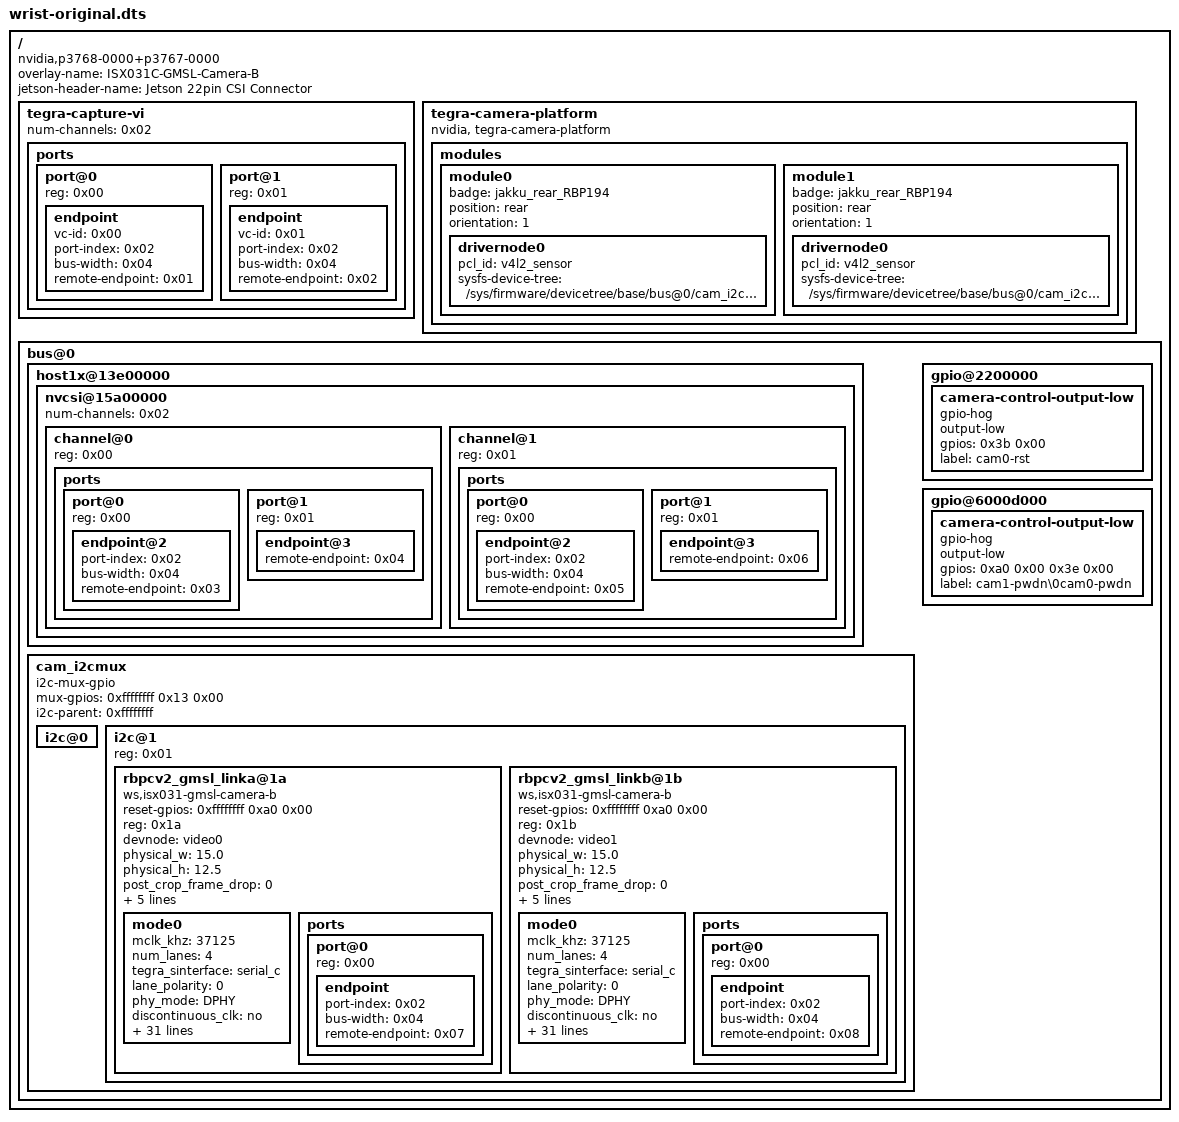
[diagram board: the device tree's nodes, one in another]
/dts-v1/;

/ {
	overlay-name = "ISX031C-GMSL-Camera-B";
	jetson-header-name = "Jetson 22pin CSI Connector";
	compatible = "nvidia,p3768-0000+p3767-0000\0nvidia,p3768-0000+p3767-0001\0nvidia,p3768-0000+p3767-0003\0nvidia,p3768-0000+p3767-0004\0nvidia,p3768-0000+p3767-0005\0nvidia,p3768-0000+p3767-0000-super\0nvidia,p3768-0000+p3767-0001-super\0nvidia,p3768-0000+p3767-0003-super\0nvidia,p3768-0000+p3767-0004-super\0nvidia,p3768-0000+p3767-0005-super";

	fragment@0 {
		target-path = "/";

		__overlay__ {

			tegra-capture-vi {
				num-channels = <0x02>;

				ports {
					#address-cells = <0x01>;
					#size-cells = <0x00>;

					port@0 {
						reg = <0x00>;
						phandle = <0x09>;

						endpoint {
							vc-id = <0x00>;
							port-index = <0x02>;
							bus-width = <0x04>;
							remote-endpoint = <0x01>;
							phandle = <0x04>;
						};
					};

					port@1 {
						reg = <0x01>;
						phandle = <0x0a>;

						endpoint {
							vc-id = <0x01>;
							port-index = <0x02>;
							bus-width = <0x04>;
							remote-endpoint = <0x02>;
							phandle = <0x06>;
						};
					};
				};
			};

			tegra-camera-platform {
				compatible = "nvidia, tegra-camera-platform";

				modules {

					module0 {
						badge = "jakku_rear_RBP194";
						position = "rear";
						orientation = "1";
						phandle = <0x0b>;

						drivernode0 {
							pcl_id = "v4l2_sensor";
							sysfs-device-tree = "/sys/firmware/devicetree/base/bus@0/cam_i2cmux/i2c@1/rbpcv2_gmsl_linka@1a";
							phandle = <0x0c>;
						};
					};

					module1 {
						badge = "jakku_rear_RBP194";
						position = "rear";
						orientation = "1";
						phandle = <0x0d>;

						drivernode0 {
							pcl_id = "v4l2_sensor";
							sysfs-device-tree = "/sys/firmware/devicetree/base/bus@0/cam_i2cmux/i2c@1/rbpcv2_gmsl_linkb@1b";
							phandle = <0x0e>;
						};
					};
				};
			};

			bus@0 {

				host1x@13e00000 {

					nvcsi@15a00000 {
						num-channels = <0x02>;
						#address-cells = <0x01>;
						#size-cells = <0x00>;

						channel@0 {
							reg = <0x00>;
							phandle = <0x0f>;

							ports {
								#address-cells = <0x01>;
								#size-cells = <0x00>;

								port@0 {
									reg = <0x00>;
									phandle = <0x10>;

									endpoint@2 {
										port-index = <0x02>;
										bus-width = <0x04>;
										remote-endpoint = <0x03>;
										phandle = <0x07>;
									};
								};

								port@1 {
									reg = <0x01>;
									phandle = <0x11>;

									endpoint@3 {
										remote-endpoint = <0x04>;
										phandle = <0x01>;
									};
								};
							};
						};

						channel@1 {
							reg = <0x01>;
							phandle = <0x12>;

							ports {
								#address-cells = <0x01>;
								#size-cells = <0x00>;

								port@0 {
									reg = <0x00>;
									phandle = <0x13>;

									endpoint@2 {
										port-index = <0x02>;
										bus-width = <0x04>;
										remote-endpoint = <0x05>;
										phandle = <0x08>;
									};
								};

								port@1 {
									reg = <0x01>;
									phandle = <0x14>;

									endpoint@3 {
										remote-endpoint = <0x06>;
										phandle = <0x02>;
									};
								};
							};
						};
					};
				};

				cam_i2cmux {
					status = "okay";
					compatible = "i2c-mux-gpio";
					#address-cells = <0x01>;
					#size-cells = <0x00>;
					mux-gpios = <0xffffffff 0x13 0x00>;
					i2c-parent = <0xffffffff>;

					i2c@0 {
					};

					i2c@1 {
						status = "okay";
						reg = <0x01>;
						#address-cells = <0x01>;
						#size-cells = <0x00>;

						rbpcv2_gmsl_linka@1a {
							reset-gpios = <0xffffffff 0xa0 0x00>;
							compatible = "ws,isx031-gmsl-camera-b";
							reg = <0x1a>;
							devnode = "video0";
							physical_w = "15.0";
							physical_h = "12.5";
							post_crop_frame_drop = "0";
							sensor_model = "isx031";
							use_sensor_mode_id = "true";
							channel = <0x01>;
							dser-addr = <0x48>;
							ser-addr = <0x40>;

							mode0 {
								mclk_khz = "37125";
								num_lanes = "4";
								tegra_sinterface = "serial_c";
								lane_polarity = "0";
								phy_mode = "DPHY";
								discontinuous_clk = "no";
								dpcm_enable = "false";
								cil_settletime = "0";
								active_w = "1920";
								active_h = "1536";
								mode_type = "yuv";
								pixel_phase = "uyvy";
								dynamic_pixel_bit_depth = "16";
								csi_pixel_bit_depth = "16";
								readout_orientation = "0";
								line_length = "2200";
								inherent_gain = "1";
								pix_clk_hz = "74250000";
								serdes_pix_clk_hz = "375000000";
								gain_factor = "10";
								framerate_factor = "1000000";
								exposure_factor = "1000000";
								min_gain_val = "16";
								max_gain_val = "170";
								step_gain_val = "1";
								default_gain = "16";
								min_hdr_ratio = "1";
								max_hdr_ratio = "1";
								min_framerate = "30000000";
								max_framerate = "30000000";
								step_framerate = "1";
								default_framerate = "30000000";
								min_exp_time = "30";
								max_exp_time = "660000";
								step_exp_time = "1";
								default_exp_time = "33334";
								embedded_metadata_height = "0";
							};

							ports {
								#address-cells = <0x01>;
								#size-cells = <0x00>;

								port@0 {
									reg = <0x00>;

									endpoint {
										status = "okay";
										port-index = <0x02>;
										bus-width = <0x04>;
										remote-endpoint = <0x07>;
										phandle = <0x03>;
									};
								};
							};
						};

						rbpcv2_gmsl_linkb@1b {
							reset-gpios = <0xffffffff 0xa0 0x00>;
							compatible = "ws,isx031-gmsl-camera-b";
							reg = <0x1b>;
							devnode = "video1";
							physical_w = "15.0";
							physical_h = "12.5";
							post_crop_frame_drop = "0";
							sensor_model = "isx031";
							use_sensor_mode_id = "true";
							channel = <0x01>;
							dser-addr = <0x48>;
							ser-addr = <0x40>;

							mode0 {
								mclk_khz = "37125";
								num_lanes = "4";
								tegra_sinterface = "serial_c";
								lane_polarity = "0";
								phy_mode = "DPHY";
								discontinuous_clk = "no";
								dpcm_enable = "false";
								cil_settletime = "0";
								active_w = "1920";
								active_h = "1536";
								mode_type = "yuv";
								pixel_phase = "uyvy";
								dynamic_pixel_bit_depth = "16";
								csi_pixel_bit_depth = "16";
								readout_orientation = "0";
								line_length = "2200";
								inherent_gain = "1";
								pix_clk_hz = "74250000";
								serdes_pix_clk_hz = "375000000";
								gain_factor = "10";
								framerate_factor = "1000000";
								exposure_factor = "1000000";
								min_gain_val = "16";
								max_gain_val = "170";
								step_gain_val = "1";
								default_gain = "16";
								min_hdr_ratio = "1";
								max_hdr_ratio = "1";
								min_framerate = "30000000";
								max_framerate = "30000000";
								step_framerate = "1";
								default_framerate = "30000000";
								min_exp_time = "30";
								max_exp_time = "660000";
								step_exp_time = "1";
								default_exp_time = "33334";
								embedded_metadata_height = "0";
							};

							ports {
								#address-cells = <0x01>;
								#size-cells = <0x00>;

								port@0 {
									reg = <0x00>;

									endpoint {
										status = "okay";
										port-index = <0x02>;
										bus-width = <0x04>;
										remote-endpoint = <0x08>;
										phandle = <0x05>;
									};
								};
							};
						};
					};
				};

				gpio@2200000 {

					camera-control-output-low {
						gpio-hog;
						output-low;
						gpios = <0x3b 0x00>;
						label = "cam0-rst";
					};
				};

				gpio@6000d000 {

					camera-control-output-low {
						gpio-hog;
						output-low;
						gpios = <0xa0 0x00 0x3e 0x00>;
						label = "cam1-pwdn\0cam0-pwdn";
					};
				};
			};
		};
	};

	__symbols__ {
		vi_port0 = "/fragment@0/__overlay__/tegra-capture-vi/ports/port@0";
		rbpcv2_gmsl_vi_in0 = "/fragment@0/__overlay__/tegra-capture-vi/ports/port@0/endpoint";
		vi_port1 = "/fragment@0/__overlay__/tegra-capture-vi/ports/port@1";
		rbpcv2_gmsl_vi_in1 = "/fragment@0/__overlay__/tegra-capture-vi/ports/port@1/endpoint";
		cam_module0 = "/fragment@0/__overlay__/tegra-camera-platform/modules/module0";
		cam_module0_drivernode0 = "/fragment@0/__overlay__/tegra-camera-platform/modules/module0/drivernode0";
		cam_module1 = "/fragment@0/__overlay__/tegra-camera-platform/modules/module1";
		cam_module1_drivernode0 = "/fragment@0/__overlay__/tegra-camera-platform/modules/module1/drivernode0";
		csi_chan0 = "/fragment@0/__overlay__/bus@0/host1x@13e00000/nvcsi@15a00000/channel@0";
		csi_chan0_port0 = "/fragment@0/__overlay__/bus@0/host1x@13e00000/nvcsi@15a00000/channel@0/ports/port@0";
		rbpcv2_gmsl_csi_in0 = "/fragment@0/__overlay__/bus@0/host1x@13e00000/nvcsi@15a00000/channel@0/ports/port@0/endpoint@2";
		csi_chan0_port1 = "/fragment@0/__overlay__/bus@0/host1x@13e00000/nvcsi@15a00000/channel@0/ports/port@1";
		rbpcv2_gmsl_csi_out0 = "/fragment@0/__overlay__/bus@0/host1x@13e00000/nvcsi@15a00000/channel@0/ports/port@1/endpoint@3";
		csi_chan1 = "/fragment@0/__overlay__/bus@0/host1x@13e00000/nvcsi@15a00000/channel@1";
		csi_chan1_port0 = "/fragment@0/__overlay__/bus@0/host1x@13e00000/nvcsi@15a00000/channel@1/ports/port@0";
		rbpcv2_gmsl_csi_in1 = "/fragment@0/__overlay__/bus@0/host1x@13e00000/nvcsi@15a00000/channel@1/ports/port@0/endpoint@2";
		csi_chan1_port1 = "/fragment@0/__overlay__/bus@0/host1x@13e00000/nvcsi@15a00000/channel@1/ports/port@1";
		rbpcv2_gmsl_csi_out1 = "/fragment@0/__overlay__/bus@0/host1x@13e00000/nvcsi@15a00000/channel@1/ports/port@1/endpoint@3";
		rbpcv2_gmsl_out0 = "/fragment@0/__overlay__/bus@0/cam_i2cmux/i2c@1/rbpcv2_gmsl_linka@1a/ports/port@0/endpoint";
		rbpcv2_gmsl_out1 = "/fragment@0/__overlay__/bus@0/cam_i2cmux/i2c@1/rbpcv2_gmsl_linkb@1b/ports/port@0/endpoint";
	};

	__fixups__ {
		gpio_aon = "/fragment@0/__overlay__/bus@0/cam_i2cmux:mux-gpios:0";
		cam_i2c = "/fragment@0/__overlay__/bus@0/cam_i2cmux:i2c-parent:0";
		gpio = "/fragment@0/__overlay__/bus@0/cam_i2cmux/i2c@1/rbpcv2_gmsl_linka@1a:reset-gpios:0\0/fragment@0/__overlay__/bus@0/cam_i2cmux/i2c@1/rbpcv2_gmsl_linkb@1b:reset-gpios:0";
	};

	__local_fixups__ {

		fragment@0 {

			__overlay__ {

				tegra-capture-vi {

					ports {

						port@0 {

							endpoint {
								remote-endpoint = <0x00>;
							};
						};

						port@1 {

							endpoint {
								remote-endpoint = <0x00>;
							};
						};
					};
				};

				bus@0 {

					host1x@13e00000 {

						nvcsi@15a00000 {

							channel@0 {

								ports {

									port@0 {

										endpoint@2 {
											remote-endpoint = <0x00>;
										};
									};

									port@1 {

										endpoint@3 {
											remote-endpoint = <0x00>;
										};
									};
								};
							};

							channel@1 {

								ports {

									port@0 {

										endpoint@2 {
											remote-endpoint = <0x00>;
										};
									};

									port@1 {

										endpoint@3 {
											remote-endpoint = <0x00>;
										};
									};
								};
							};
						};
					};

					cam_i2cmux {

						i2c@1 {

							rbpcv2_gmsl_linka@1a {

								ports {

									port@0 {

										endpoint {
											remote-endpoint = <0x00>;
										};
									};
								};
							};

							rbpcv2_gmsl_linkb@1b {

								ports {

									port@0 {

										endpoint {
											remote-endpoint = <0x00>;
										};
									};
								};
							};
						};
					};
				};
			};
		};
	};
};
